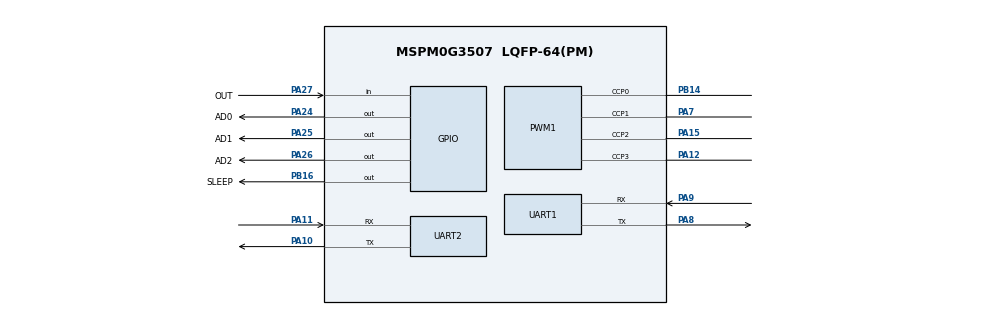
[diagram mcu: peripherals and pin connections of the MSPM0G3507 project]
/**
 * These arguments were used when this file was generated. They will be automatically applied on subsequent loads
 * via the GUI or CLI. Run CLI with '--help' for additional information on how to override these arguments.
 * @cliArgs --device "MSPM0G350X" --part "Default" --package "LQFP-64(PM)" --product "mspm0_sdk@2.10.00.04"
 * @v2CliArgs --device "MSPM0G3507" --package "LQFP-64(PM)" --product "mspm0_sdk@2.10.00.04"
 * @versions {"tool":"1.26.2+4477"}
 */

/**
 * Import the modules used in this configuration.
 */
const GPIO   = scripting.addModule("/ti/driverlib/GPIO", {}, false);
const GPIO1  = GPIO.addInstance();
const GPIO2  = GPIO.addInstance();
const GPIO3  = GPIO.addInstance();
const PWM    = scripting.addModule("/ti/driverlib/PWM", {}, false);
const PWM1   = PWM.addInstance();
const SYSCTL = scripting.addModule("/ti/driverlib/SYSCTL");
const TIMER  = scripting.addModule("/ti/driverlib/TIMER", {}, false);
const TIMER1 = TIMER.addInstance();
const UART   = scripting.addModule("/ti/driverlib/UART", {}, false);
const UART1  = UART.addInstance();
const UART2  = UART.addInstance();

/**
 * Write custom configuration values to the imported modules.
 */
GPIO1.$name                         = "GRP_GRAY";
GPIO1.associatedPins.create(3);
GPIO1.associatedPins[0].$name       = "AD0";
GPIO1.associatedPins[0].pin.$assign = "PA24";
GPIO1.associatedPins[1].$name       = "AD1";
GPIO1.associatedPins[1].pin.$assign = "PA25";
GPIO1.associatedPins[2].$name       = "AD2";
GPIO1.associatedPins[2].pin.$assign = "PA26";

const Board = scripting.addModule("/ti/driverlib/Board", {}, false);

GPIO2.$name                         = "GRP_GRAY_OUT";
GPIO2.associatedPins[0].$name       = "OUT";
GPIO2.associatedPins[0].direction   = "INPUT";
GPIO2.associatedPins[0].pin.$assign = "PA27";

GPIO3.$name                         = "GRP_SLEEP";
GPIO3.associatedPins[0].$name       = "SLEEP";
GPIO3.associatedPins[0].pin.$assign = "PB16";

PWM1.$name                              = "PWM_DRIVE";
PWM1.timerCount                         = 3200;
PWM1.ccIndex                            = [0,1,2,3];
PWM1.PWM_CHANNEL_0.$name                = "ti_driverlib_pwm_PWMTimerCC0";
PWM1.PWM_CHANNEL_1.$name                = "ti_driverlib_pwm_PWMTimerCC1";
PWM1.ccp0PinConfig.direction            = scripting.forceWrite("OUTPUT");
PWM1.ccp0PinConfig.hideOutputInversion  = scripting.forceWrite(false);
PWM1.ccp0PinConfig.onlyInternalResistor = scripting.forceWrite(false);
PWM1.ccp0PinConfig.passedPeripheralType = scripting.forceWrite("Digital");
PWM1.ccp0PinConfig.$name                = "ti_driverlib_gpio_GPIOPinGeneric1";
PWM1.ccp1PinConfig.direction            = scripting.forceWrite("OUTPUT");
PWM1.ccp1PinConfig.hideOutputInversion  = scripting.forceWrite(false);
PWM1.ccp1PinConfig.onlyInternalResistor = scripting.forceWrite(false);
PWM1.ccp1PinConfig.passedPeripheralType = scripting.forceWrite("Digital");
PWM1.ccp1PinConfig.$name                = "ti_driverlib_gpio_GPIOPinGeneric2";
PWM1.peripheral.$assign                 = "TIMA0";
PWM1.peripheral.ccp0Pin.$assign         = "PB14";
PWM1.peripheral.ccp1Pin.$assign         = "PA7";
PWM1.peripheral.ccp2Pin.$assign         = "PA15";
PWM1.peripheral.ccp3Pin.$assign         = "PA12";
PWM1.PWM_CHANNEL_2.$name                = "ti_driverlib_pwm_PWMTimerCC2";
PWM1.PWM_CHANNEL_3.$name                = "ti_driverlib_pwm_PWMTimerCC3";
PWM1.ccp2PinConfig.$name                = "ti_driverlib_gpio_GPIOPinGeneric3";
PWM1.ccp3PinConfig.$name                = "ti_driverlib_gpio_GPIOPinGeneric4";

SYSCTL.forceDefaultClkConfig = true;

TIMER1.$name                       = "TIMER_0";
TIMER1.timerMode                   = "PERIODIC";
TIMER1.timerClkDiv                 = 1;
TIMER1.timerPeriod                 = "0.5 ms";
TIMER1.interrupts                  = ["ZERO"];
TIMER1.peripheral.$assign          = "TIMG0";

/* HLK-AS201 陀螺仪串口: 115200-8-N-1, 使能 RX 中断 */
UART1.$name                            = "UART_GYRO";
UART1.enabledInterrupts                = ["RX"];
UART1.targetBaudRate                   = 115200;
UART1.peripheral.$assign               = "UART1";
UART1.peripheral.rxPin.$assign         = "PA9";
UART1.peripheral.txPin.$assign         = "PA8";
UART1.txPinConfig.$name                = "ti_driverlib_gpio_GPIOPinGeneric5";
UART1.rxPinConfig.$name                = "ti_driverlib_gpio_GPIOPinGeneric6";

/* JDY-31 蓝牙串口调试: 9600-8-N-1, 仅 TX 发送, 无需 RX 中断 */
UART2.$name                            = "UART_BT";
UART2.targetBaudRate                   = 115200;
UART2.peripheral.$assign               = "UART0";
UART2.peripheral.txPin.$assign         = "PA10";
UART2.peripheral.rxPin.$assign         = "PA11";
UART2.txPinConfig.$name                = "ti_driverlib_gpio_GPIOPinGeneric7";
UART2.rxPinConfig.$name                = "ti_driverlib_gpio_GPIOPinGeneric8";

/**
 * Pinmux solution for unlocked pins/peripherals. This ensures that minor changes to the automatic solver in a future
 * version of the tool will not impact the pinmux you originally saw.  These lines can be completely deleted in order to
 * re-solve from scratch.
 */
Board.peripheral.$suggestSolution          = "DEBUGSS";
Board.peripheral.swclkPin.$suggestSolution = "PA20";
Board.peripheral.swdioPin.$suggestSolution = "PA19";
SYSCTL.peripheral.$suggestSolution         = "SYSCTL";
TIMER1.peripheral.$suggestSolution         = "TIMG0";
